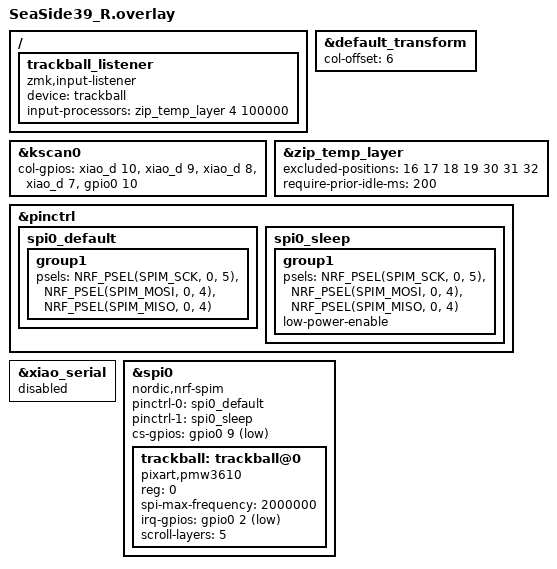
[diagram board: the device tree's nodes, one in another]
#include "SeaSide39.dtsi"
#include <input/processors.dtsi>

&default_transform {
    col-offset = <6>;
};

/* キーマトリクスの設定 */
&kscan0 {
        col-gpios
            = <&xiao_d 10 GPIO_ACTIVE_HIGH>
            , <&xiao_d 9 GPIO_ACTIVE_HIGH> 
            , <&xiao_d 8 GPIO_ACTIVE_HIGH> 
            , <&xiao_d 7 GPIO_ACTIVE_HIGH> 
            , <&gpio0 10 GPIO_ACTIVE_HIGH>
            ;
};

/* AML: 非マウスキーを押したら解除、キー入力直後は誤爆防止 */
&zip_temp_layer {
    excluded-positions = <
        16  // MB1
        17  // MB3
        18  // MB2
        19  // mo 5 (SCROLLレイヤー)
        30  // LCTRL
        31  // LEFT_ALT
        32  // LEFT_WIN
        // 33 mt LEFT_SHIFT LANG2 → タップ時のみ解除
        // 34 lt 1 SPACE          → タップ時のみ解除
        // 35 lt 2 LANG1          → タップ時のみ解除
        // 36 BACKSPACE → AML解除
        // 37 lt 3 ENTER → AML解除
        // 38 lt 4 ESCAPE → AML解除
    >;

    require-prior-idle-ms = <200>;
};

/* Trackball のリスナー */
/ {
    trackball_listener {
        compatible = "zmk,input-listener";
        device = <&trackball>;
        input-processors = <&zip_temp_layer 4 100000>;
    };
};

/* SPI 設定 */
&pinctrl {
    spi0_default: spi0_default {
        group1 {
            psels = <NRF_PSEL(SPIM_SCK, 0, 5)>,
                <NRF_PSEL(SPIM_MOSI, 0, 4)>,
                <NRF_PSEL(SPIM_MISO, 0, 4)>;
        };
    };

    spi0_sleep: spi0_sleep {
        group1 {
            psels = <NRF_PSEL(SPIM_SCK, 0, 5)>,
                <NRF_PSEL(SPIM_MOSI, 0, 4)>,
                <NRF_PSEL(SPIM_MISO, 0, 4)>;
            low-power-enable;
        };
    };
};

/* シリアルを無効化 */
&xiao_serial { status = "disabled"; };

/* SPI デバイス (トラックボール) */
&spi0 {
    status = "okay";
    compatible = "nordic,nrf-spim";
    pinctrl-0 = <&spi0_default>;
    pinctrl-1 = <&spi0_sleep>;
    pinctrl-names = "default", "sleep";
    cs-gpios = <&gpio0 9 GPIO_ACTIVE_LOW>;

    trackball: trackball@0 {
        status = "okay";
        compatible = "pixart,pmw3610";
        reg = <0>;
        spi-max-frequency = <2000000>;
        irq-gpios = <&gpio0 2 (GPIO_ACTIVE_LOW | GPIO_PULL_UP)>;
        scroll-layers = <5>;
    };
};
